# STM32F412CEU6 register map
File version: 1.0
Registers are 32-bit, access not given, reset 0x0 unless marked. A register's access mark holds for its fields unless they carry their own. Offsets are from the block's base; [hi:lo] are bit positions; {n}, {i} and the like mark numbered series; 'fields as' and 'values as' point back to an identical list.

## ADC1
Base 0x40012000
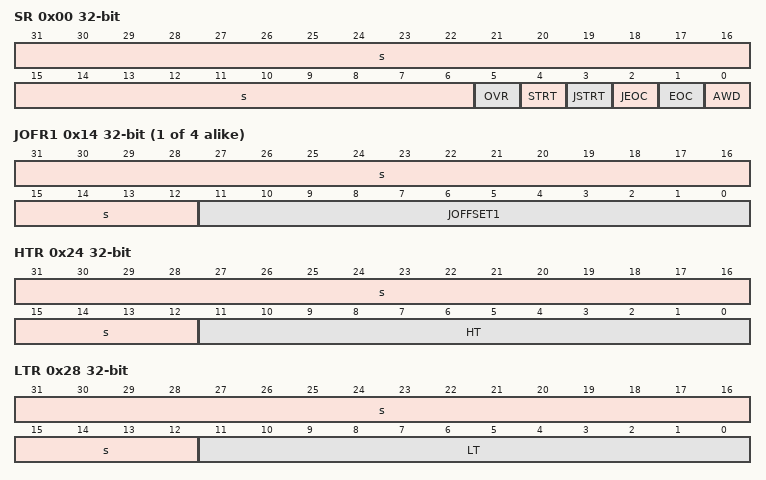
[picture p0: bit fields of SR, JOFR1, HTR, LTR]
0x00 SR
  [31:6] s, [5] OVR, [4] STRT, [3] JSTRT, [2] JEOC, [1] EOC, [0] AWD
0x04 CR1
  [26] OVRIE, [25:24] RES, [23] AWDEN, [22] JAWDEN, [31:16] s, [15:13] DISCNUM, [12] JDISCEN, [11] DISCEN, [10] JAUTO, [9] AWDSGL, [8] SCAN, [7] JEOCIE, [6] AWDIE, [5] EOCIE, [4:0] AWDCH
0x08 CR2
  [30] SWSTART, [29:28] EXTEN, [27:24] EXTSEL, [22] JSWSTART, [21:20] JEXTEN, [19:16] JEXTSEL, [11] ALIGN, [10] EOCS, [9] DDS, [8] DMA, [31:2] s, [1] CONT, [0] ADON
0x0C SMPR1
  [31:0] SMP
0x10 SMPR2
  [31:0] SMP
{0x10+4i} JOFR{i} (i=1..4)
  [31:12] s, [11:0] JOFFSET{i}
0x24 HTR
  [31:12] s, [11:0] HT
0x28 LTR
  [31:12] s, [11:0] LT
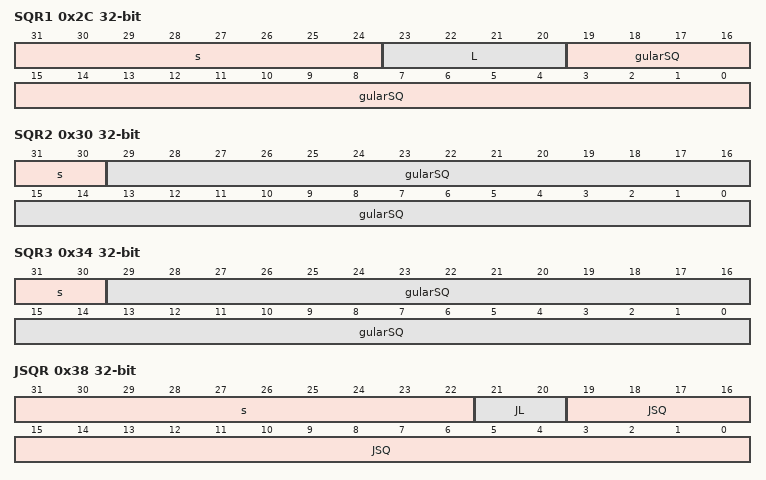
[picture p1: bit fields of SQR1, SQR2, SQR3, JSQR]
0x2C SQR1
  [31:24] s, [23:20] L, [19:0] gularSQ
0x30 SQR2
  [31:30] s, [29:0] gularSQ
0x34 SQR3
  [31:30] s, [29:0] gularSQ
0x38 JSQR
  [31:22] s, [21:20] JL, [19:0] JSQ
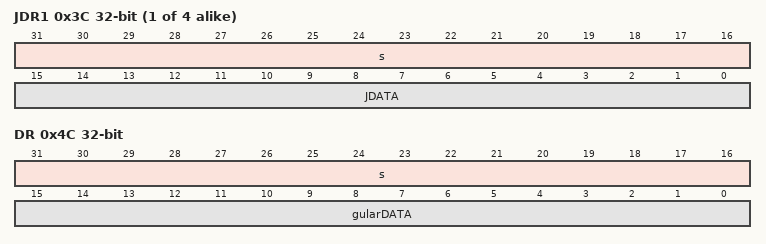
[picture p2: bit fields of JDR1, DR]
{0x38+4i} JDR{i} (i=1..4)
  [31:16] s, [15:0] JDATA
0x4C DR
  [31:16] s, [15:0] gularDATA

## SDIO
Base 0x40012C00
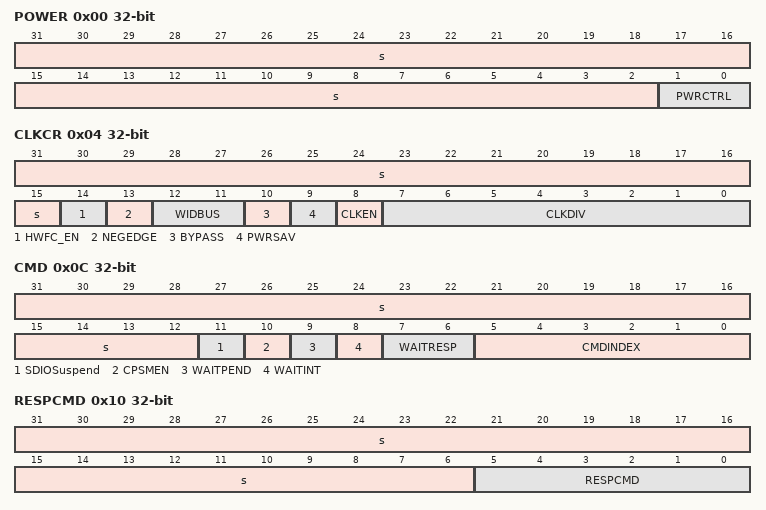
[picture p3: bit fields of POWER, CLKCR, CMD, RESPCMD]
0x00 POWER
  [31:2] s, [1:0] PWRCTRL
0x04 CLKCR
  [31:15] s, [14] HWFC_EN, [13] NEGEDGE, [12:11] WIDBUS, [10] BYPASS, [9] PWRSAV, [8] CLKEN, [7:0] CLKDIV
0x08 ARG
  [31:0] CMDARG
0x0C CMD
  [31:12] s, [11] SDIOSuspend, [10] CPSMEN, [9] WAITPEND, [8] WAITINT, [7:6] WAITRESP, [5:0] CMDINDEX
0x10 RESPCMD
  [31:6] s, [5:0] RESPCMD
{0x10+4i} RESP{i} (i=1..4)
  [31:0] CARDSTATUS{i}
0x24 DTIMER
  [31:0] DATATIME
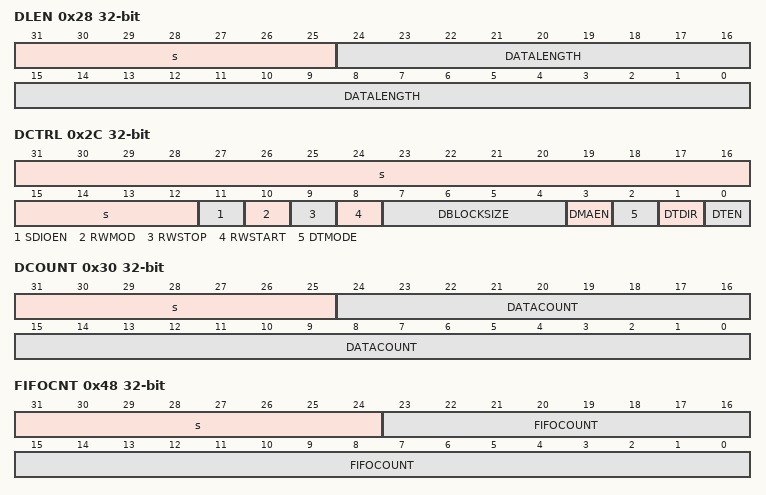
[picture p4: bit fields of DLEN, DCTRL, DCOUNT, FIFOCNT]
0x28 DLEN
  [31:25] s, [24:0] DATALENGTH
0x2C DCTRL
  [31:12] s, [11] SDIOEN, [10] RWMOD, [9] RWSTOP, [8] RWSTART, [7:4] DBLOCKSIZE, [3] DMAEN, [2] DTMODE, [1] DTDIR, [0] DTEN
0x30 DCOUNT
  [31:25] s, [24:0] DATACOUNT
0x34 STA
  [22] SDIOIT, [21] RXDAVL, [20] TXDAVL, [19] RXFIFOE, [18] TXFIFOE, [17] RXFIFOF, [16] TXFIFOF, [15] RXFIFOHF, [14] TXFIFOHE, [13] RXACT, [12] TXACT, [11] CMDACT, [10] DBCKEND, [31:9] s, [8] DATAEND, [7] CMDSENT, [6] CMDREND, [5] RXOVERR, [4] TXUNDERR, [3] DTIMEOUT, [2] CTIMEOUT, [1] DCRCFAIL, [0] CCRCFAIL
0x38 ICR
  [22] SDIOITC, [10] DBCKENDC, [31:9] s, [8] DATAENDC, [7] CMDSENTC, [6] CMDRENDC, [5] RXOVERRC, [4] TXUNDERRC, [3] DTIMEOUTC, [2] CTIMEOUTC, [1] DCRCFAILC, [0] CCRCFAILC
0x3C MASK
  [22] SDIOITIE, [21] RXDAVLIE, [20] TXDAVLIE, [19] RXFIFOEIE, [18] TXFIFOEIE, [17] RXFIFOFIE, [16] TXFIFOFIE, [15] RXFIFOHFIE, [14] TXFIFOHEIE, [13] RXACTIE, [12] TXACTIE, [11] CMDACTIE, [10] DBCKENDIE, [31:9] s, [8] DATAENDIE, [7] CMDSENTIE, [6] CMDRENDIE, [5] RXOVERRIE, [4] TXUNDERRIE, [3] DTIMEOUTIE, [2] CTIMEOUTIE, [1] DCRCFAILIE, [0] CCRCFAILIE
0x48 FIFOCNT
  [31:24] s, [23:0] FIFOCOUNT
0x80 FIFO
  [31:0] FIF0Data

## SYSCFG
Base 0x40013800
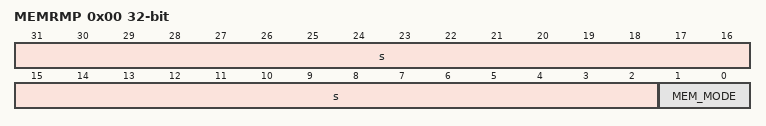
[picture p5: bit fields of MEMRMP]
0x00 MEMRMP
  [31:2] s, [1:0] MEM_MODE
0x04 PMC
{0x4+4i} EXTICR{i} (i=1..4)
0x1C CFGR2
0x20 CMPCR
0x24 CFGR

## EXTI
Base 0x40013C00
0x00 IMR
0x04 EMR
0x08 RTSR
0x0C FTSR
0x10 SWIER
0x14 PR

## DFSDM1
Base 0x40016000
0x00 CH0CFGR1
  [31] DFSDMEN, [30] CKOUTSRC, [23:16] CKOUTDIV, [15:14] DATPACK, [13:12] DATMPX, [8] CHINSEL, [7] CHEN, [6] CKABEN, [5] SCDEN, [29:4] s, [3:2] SPICKSEL, [1:0] SITP
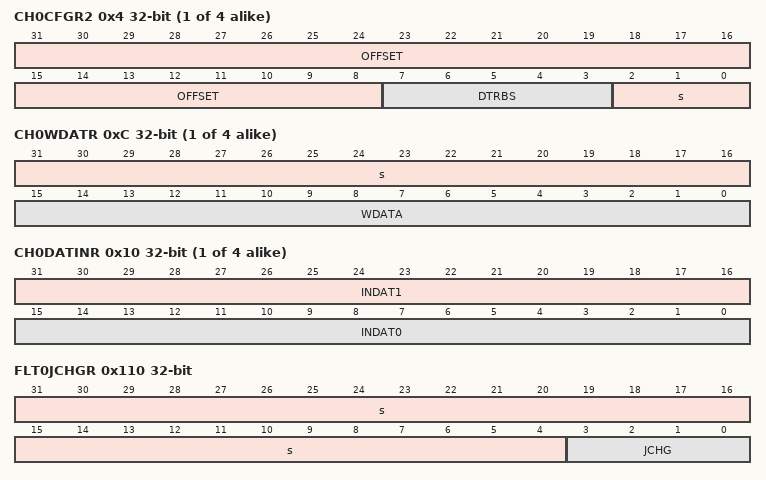
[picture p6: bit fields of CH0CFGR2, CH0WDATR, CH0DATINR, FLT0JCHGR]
{0x4+0x20*i} CH{i}CFGR2 (i=0..3)
  [31:8] OFFSET, [7:3] DTRBS, [2:0] s
{0x8+0x20*i} CH{i}AWSCDR (i=0..3)
  [23:22] AWFORD, [20:16] AWFOSR, [15:12] BKSCD, [31:8] s, [7:0] SCDT
{0xC+0x20*i} CH{i}WDATR (i=0..3)
  [31:16] s, [15:0] WDATA
{0x10+0x20*i} CH{i}DATINR (i=0..3)
  [31:16] INDAT1, [15:0] INDAT0
{0x0+0x20*i} CH{i}CFGR1 (i=1..3)
  [15:14] DATPACK, [13:12] DATMPX, [8] CHINSEL, [7] CHEN, [6] CKABEN, [5] SCDEN, [31:4] s, [3:2] SPICKSEL, [1:0] SITP
0x100 FLT0CR1
  [30] AWFSEL, [29] FAST, [25:24] RCH, [21] RDMAEN, [19] RSYNC, [18] RCONT, [17] RSWSTART, [14:13] JEXTEN, [10:8] JEXTSEL, [5] JDMAEN, [4] JSCAN, [3] JSYNC, [31:2] s, [1] JSWSTART, [0] DFEN
0x104 FLT0CR2
  [19:16] AWDCH, [11:8] EXCH, [31:7] s, [6] CKABIE, [5] SCDIE, [4] AWDIE, [3] ROVRIE, [2] JOVRIE, [1] REOCIE, [0] JEOCIE
0x108 FLT0ISR
  [27:24] SCDF, [19:16] CKABF, [14] RCIP, [13] JCIP, [31:5] s, [4] AWDF, [3] ROVRF, [2] JOVRF, [1] REOCF, [0] JEOCF
0x10C FLT0ICR
  [27:24] CLRSCDF, [19:16] CLRCKABF, [3] CLRROVRF, [2] CLRJOVRF, [31:0] s
0x110 FLT0JCHGR
  [31:4] s, [3:0] JCHG
0x114 FLT0FCR
  [31:29] FORD, [25:16] FOSR, [28:8] s, [7:0] IOSR
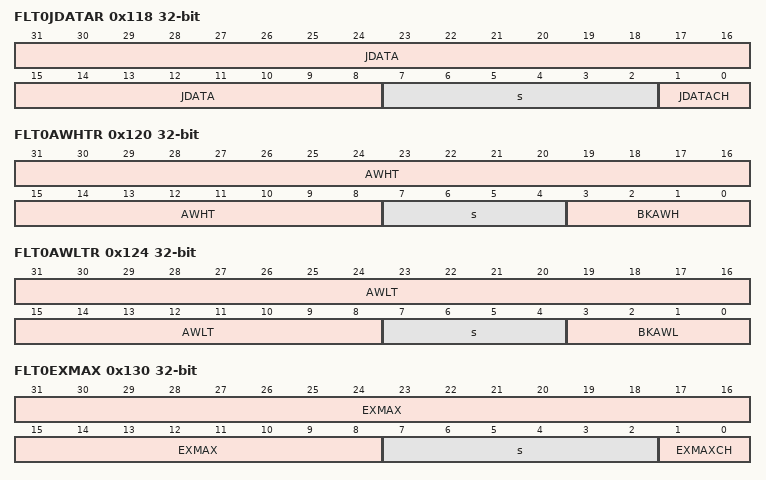
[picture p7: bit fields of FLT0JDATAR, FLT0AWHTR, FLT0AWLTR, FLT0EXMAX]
0x118 FLT0JDATAR
  [31:8] JDATA, [7:2] s, [1:0] JDATACH
0x11C FLT0RDATAR
  [31:8] RDATA, [4] RPEND, [7:2] s, [1:0] RDATACH
0x120 FLT0AWHTR
  [31:8] AWHT, [7:4] s, [3:0] BKAWH
0x124 FLT0AWLTR
  [31:8] AWLT, [7:4] s, [3:0] BKAWL
0x128 FLT0AWSR
  [11:8] AWHTF, [31:4] s, [3:0] AWLTF
0x12C FLT0AWCFR
  [11:8] CLRAWHTF, [31:4] s, [3:0] CLRAWLTF
0x130 FLT0EXMAX
  [31:8] EXMAX, [7:2] s, [1:0] EXMAXCH
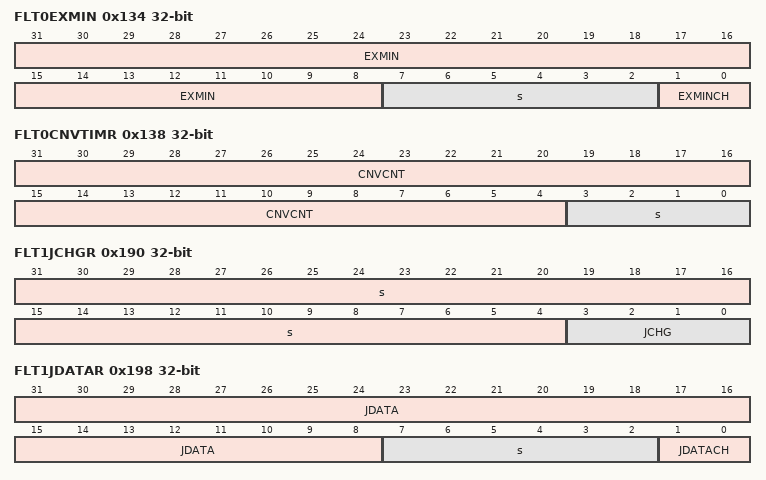
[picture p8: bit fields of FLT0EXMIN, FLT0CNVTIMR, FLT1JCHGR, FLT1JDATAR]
0x134 FLT0EXMIN
  [31:8] EXMIN, [7:2] s, [1:0] EXMINCH
0x138 FLT0CNVTIMR
  [31:4] CNVCNT, [3:0] s
0x180 FLT1CR1
  fields as FLT0CR1
0x184 FLT1CR2
  [19:16] AWDCH, [11:8] EXCH, [31:5] s, [4] AWDIE, [3] ROVRIE, [2] JOVRIE, [1] REOCIE, [0] JEOCIE
0x188 FLT1ISR
  [14] RCIP, [13] JCIP, [31:5] s, [4] AWDF, [3] ROVRF, [2] JOVRF, [1] REOCF, [0] JEOCF
0x18C FLT1ICR
  [3] CLRROVRF, [2] CLRJOVRF, [31:0] s
0x190 FLT1JCHGR
  [31:4] s, [3:0] JCHG
0x194 FLT1FCR
  [31:29] FORD, [25:16] FOSR, [28:8] s, [7:0] IOSR
0x198 FLT1JDATAR
  [31:8] JDATA, [7:2] s, [1:0] JDATACH
0x19C FLT1RDATAR
  [31:8] RDATA, [4] RPEND, [7:2] s, [1:0] RDATACH
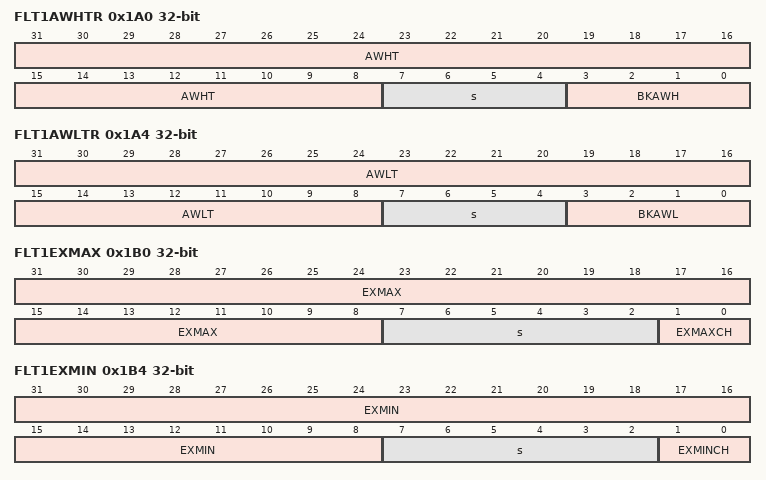
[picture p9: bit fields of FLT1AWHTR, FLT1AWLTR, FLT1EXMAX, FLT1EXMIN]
0x1A0 FLT1AWHTR
  [31:8] AWHT, [7:4] s, [3:0] BKAWH
0x1A4 FLT1AWLTR
  [31:8] AWLT, [7:4] s, [3:0] BKAWL
0x1A8 FLT1AWSR
  [11:8] AWHTF, [31:4] s, [3:0] AWLTF
0x1AC FLT1AWCFR
  [11:8] CLRAWHTF, [31:4] s, [3:0] CLRAWLTF
0x1B0 FLT1EXMAX
  [31:8] EXMAX, [7:2] s, [1:0] EXMAXCH
0x1B4 FLT1EXMIN
  [31:8] EXMIN, [7:2] s, [1:0] EXMINCH
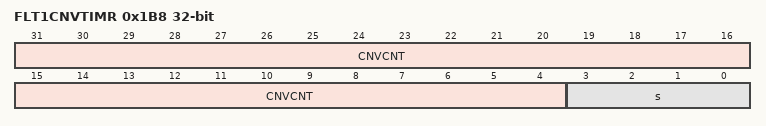
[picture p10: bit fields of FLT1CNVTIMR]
0x1B8 FLT1CNVTIMR
  [31:4] CNVCNT, [3:0] s
